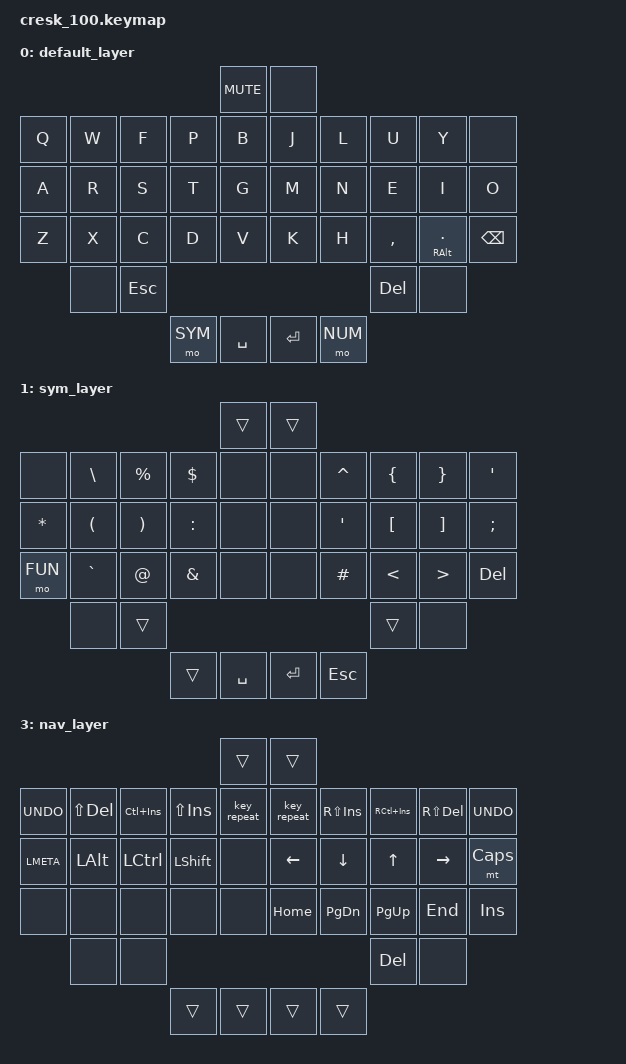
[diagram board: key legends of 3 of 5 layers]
/*
 * Copyright (c) 2022 The ZMK Contributors
 *
 * SPDX-License-Identifier: MIT
 */

#include <behaviors.dtsi>
#include <dt-bindings/zmk/keys.h>


#define COLEMAK 0
#define SYM 1
#define NUM 2
#define NAV 3
#define FUN 4

&caps_word {
    continue-list = <UNDERSCORE MINUS BACKSPACE>;
};

&mt {
    flavor = "tap-preferred";
    tapping_term_ms = <200>;
    quick_tap_ms = <75>;
};

&sk {
    release-after-ms = <600>;
    quick-release;
};

&sl {
    release-after-ms = <600>;
};

/ {
    behaviors {
        skq: sticky_key_quick_release {
            compatible = "zmk,behavior-sticky-key";
            label = "STICKY_KEY_QUICK_RELEASE";
            #binding-cells = <1>;
            bindings = <&kp>;
            release-after-ms = <1000>;
            quick-release;
        };
    };

    combos {
        compatible = "zmk,combos";
        combo_gm_capsword {
            layers = <0 1 2 3 4>;
            timeout-ms = <100>;
            // G + M
            key-positions = <16 17>;
            bindings = <&caps_word>;
        };
        combo_wf_tab {
            layers = <0 1 2 3 4>;
            timeout-ms = <100>;
            // W + F
            key-positions = <3 4>;
            bindings = <&kp TAB>;
        };
        combo_uy_shift {
            layers = <0 1 2 3 4>;
            timeout-ms = <100>;
            // U + Y
            key-positions = <9 10>;
            bindings = <&skq LSHFT>;
        };
        combo_xc_ctrl {
            layers = <0 1 2 3 4>;
            timeout-ms = <100>;
            // Z + X
            key-positions = <23 24>;
            bindings = <&sk LCTL>;
        };
        combo_commadot_tab {
            layers = <0 1 2 3 4>;
            timeout-ms = <100>;
            // , + . = shift
            key-positions = <29 30>;
            bindings = <&kp TAB>;
        };
        combo_opt {
            layers = <0 1 2 3 4>;
            timeout-ms = <100>;
            // SYM + SPC = CMD
            key-positions = <38 30>;
            bindings = <&sk LCMD>;
        };
        combo_cmd {
            layers = <0 1 2 3 4>;
            timeout-ms = <100>;
            // NUM + ENT = OPT
            key-positions = <36 37>;
            bindings = <&sk LALT>;
        };
        combo_bspc {
            layers = <0 1 2 3 4>;
            timeout-ms = <100>;
            // SPC + ENT = BSPC
            key-positions = <37 38>;
            bindings = <&kp BSPC>;
        };
        combo_wp_q {
            layers = <0 1 2 3 4>;
            timeout-ms = <100>;
            // W + P = Q
            key-positions = <3 5>;
            bindings = <&kp Q>;
        };
    };

    keymap {
        compatible = "zmk,keymap";

        default_layer {
            bindings = <
                                                                             &kp C_MUTE         &none
&kp Q            &kp W                &kp F             &kp P                &kp B              &kp J            &kp L               &kp U           &kp Y           &none
&kp A            &kp R                &kp S             &kp T                &kp G              &kp M            &kp N               &kp E           &kp I           &kp O
&kp Z            &kp X                &kp C             &kp D                &kp V              &kp K            &kp H               &kp COMMA       &mt RALT DOT    &kp BSPC
                 &none                &kp ESC                                                                                        &kp DEL     &none
                                                        &mo SYM              &kp SPACE          &kp RET          &mo NUM
            >;

            sensor-bindings = <&inc_dec_kp C_VOL_UP C_VOL_DN
                               &inc_dec_kp PG_UP PG_DN>;
        }
    ;

        sym_layer {
            bindings = <
                                                                             &trans             &trans
&none            &kp BSLH             &kp PRCNT         &kp DLLR             &none              &none            &kp CARET           &kp LBRC        &kp RBRC        &kp APOS
&kp STAR         &kp LPAR             &kp RPAR          &kp COLON            &none              &none            &kp SQT             &kp LBKT        &kp RBKT        &kp SEMI
&mo FUN          &kp GRAVE            &kp AT            &kp AMPS             &none              &none            &kp HASH            &kp LT          &kp GT          &kp DEL                         
                 &none                &trans                                                                                         &trans          &none
                                                        &trans               &kp SPACE          &kp RET          &kp ESC
            >;
        };

        num_layer {
            bindings = <
                                                                             &trans             &trans
&kp BSPC         &kp N4               &kp N5            &kp N6               &none              &none            &kp PIPE            &kp MINUS       &kp FSLH        &none
&kp DOT          &kp N1               &kp N2            &kp N3               &none              &none            &kp DQT             &kp UNDER       &kp EQUAL       &mo NAV
&kp TILDE        &kp N7               &kp N8            &kp N9               &none              &none            &kp PLUS            &kp QMARK       &kp EXCL        &kp DEL                                                                &none           &none
                 &none                &kp DOT                                                                                        &none           &none
                                                        &kp N0               &kp SPACE          &kp RET          &trans
            >;
        };

        nav_layer {
            bindings = <
                                                                             &trans             &trans
&kp K_UNDO       &kp LS(DEL)          &kp LC(INS)       &kp LS(INS)          &key_repeat        &key_repeat      &kp RS(INS)         &kp RC(INS)     &kp RS(DEL)     &kp K_UNDO
&kp LMETA        &kp LALT             &kp LCTRL         &kp LSHFT            &none              &kp LEFT         &kp DOWN            &kp UP          &kp RIGHT       &mt CAPS
&none            &none                &none             &none                &none              &kp HOME         &kp PAGE_DOWN       &kp PAGE_UP     &kp END         &kp INS
                 &none                &none                                                                                          &kp DEL         &none
                                                        &trans               &trans             &trans           &trans
            >;
        };

        fun_layer {
            bindings = <
                                                                             &trans             &trans
&none            &kp F6               &kp F5            &kp F4               &kp F10            &none            &none               &none           &none           &none                                                                             &trans             &trans
&kp CAPS         &kp F3               &kp F2            &kp F1               &kp F11            &kp K_MUTE       &kp C_VOL_DN        &kp C_VOL_UP    &kp C_BRI_DN    &kp C_BRI_UP
&trans           &kp F9               &kp F8            &kp F7               &kp F12            &none            &none               &none           &none           &none                                       
                 &none                &trans                                                                                         &trans          &trans
                                                        &trans               &trans             &none            &trans
            >;
        };
    };
};
